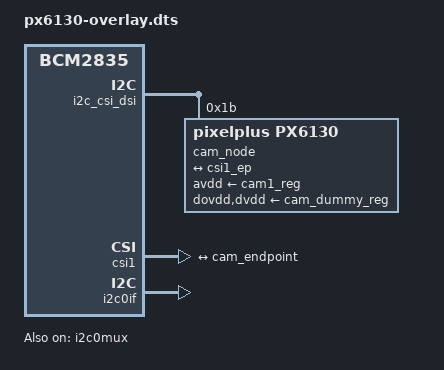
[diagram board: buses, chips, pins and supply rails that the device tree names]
// SPDX-License-Identifier: GPL-2.0-only
// Definitions for Analog Devices ADV7282-M video to CSI2 bridge on VC I2C bus
/dts-v1/;
/plugin/;

/{
	compatible = "brcm,bcm2835";

	i2c_frag: fragment@0 {
		target = <&i2c_csi_dsi>;
		__overlay__ {
			#address-cells = <1>;
			#size-cells = <0>;
			status = "okay";
			
			cam_node: px6130@1B {
				compatible = "pixelplus,px6130";
				reg = <0x1B>;
				status = "disabled";
				
				clocks = <&cam1_clk>;
				
				avdd-supply = <&cam1_reg>;
				dovdd-supply = <&cam_dummy_reg>;
				dvdd-supply = <&cam_dummy_reg>;
				
				port {
					cam_endpoint: endpoint {
						clock-lanes = <0>;
						data-lanes = <1 2>;
						link-frequencies =
							/bits/ 64 <292000000>;
					};
				};
			};
		};
	};
	csi_frag: fragment@1 {
		target = <&csi1>;
		csi: __overlay__ {
			status = "okay";
			brcm,media-controller;
			
			port {
				csi1_ep: endpoint {
					remote-endpoint = <&cam_endpoint>;
					data-lanes = <1 2>;
				};
			};
		};
	};
	fragment@2 {
		target = <&i2c0if>;
		__overlay__ {
			status = "okay";
		};
	};

	fragment@3 {
		target = <&i2c0mux>;
		__overlay__ {
			status = "okay";
		};
	};

	reg_frag: fragment@4 {
		target = <&cam1_reg>;
		__overlay__ {
			startup-delay-us = <20000>;
		};
	};
	clk_frag: fragment@5 {
		target = <&cam1_clk>;
		__overlay__ {
			status = "okay";
			clock-frequency = <25000000>;
		};
	};

	__overrides__ {
		media-controller = <&csi>,"brcm,media-controller?";
		link-frequency = <&cam_endpoint>,"link-frequencies#0";
		cam0 = <&i2c_frag>, "target:0=",<&i2c_csi_dsi0>,
		       <&csi_frag>, "target:0=",<&csi0>,
		       <&reg_frag>, "target:0=",<&cam0_reg>,
		       <&clk_frag>, "target:0=",<&cam0_clk>,
		       <&cam_node>, "clocks:0=",<&cam0_clk>,
		       <&cam_node>, "avdd-supply:0=",<&cam0_reg>;
	};
};

&cam_node {
	status = "okay";
};

&cam_endpoint {
	remote-endpoint = <&csi1_ep>;
};
